# ipro7 register map
Vendor: intelpro; Series: BTBLE
CPU: ipro7, little endian
Registers are 32-bit, read-write, reset 0x0 unless marked. A register's access mark holds for its fields unless they carry their own. Offsets are from the block's base; [hi:lo] are bit positions; {n}, {i} and the like mark numbered series; <NAME> marks a mode.

## DMA
Base 0x30082000
0x00 DMA_IntStatus (reset mask 0xFFFFFF00)
  [7:0] IntStatus ro — Status of the DMA interrupts after masking
0x04 DMA_IntTCStatus (reset mask 0xFFFFFF00)
  [7:0] IntTCStatus ro — Interrupt terminal count request status
0x08 DMA_IntTCClear
  [7:0] IntTCClear wo — Terminal count request clear
0x0C DMA_IntErrorStatus (reset mask 0xFFFFFF00)
  [7:0] IntErrorStatus ro — Interrupt error status
0x10 DMA_IntErrClr
  [7:0] IntErrClr wo — Interrupt error clear
0x14 DMA_RawIntTCStatus (reset mask 0xFFFFFF00)
  [7:0] RawIntTCStatus ro — Status of the terminal count interrupt prior to masking
0x18 DMA_RawIntErrorStatus (reset mask 0xFFFFFF00)
  [7:0] RawIntErrorStatus ro — Status of the error interrupt prior to masking
0x1C DMA_EnbldChns (reset mask 0xFFFFFF00)
  [7:0] EnabledChannels ro — Channel enable status
0x20 DMA_SoftBReq
  [31:0] SoftBReq — Software burst request
0x24 DMA_SoftSReq
  [31:0] SoftSReq — Software single request
0x28 DMA_SoftLBReq
  [31:0] SoftLBReq — Software last burst request
0x2C DMA_SoftLSReq
  [31:0] SoftLSReq — Software last single request
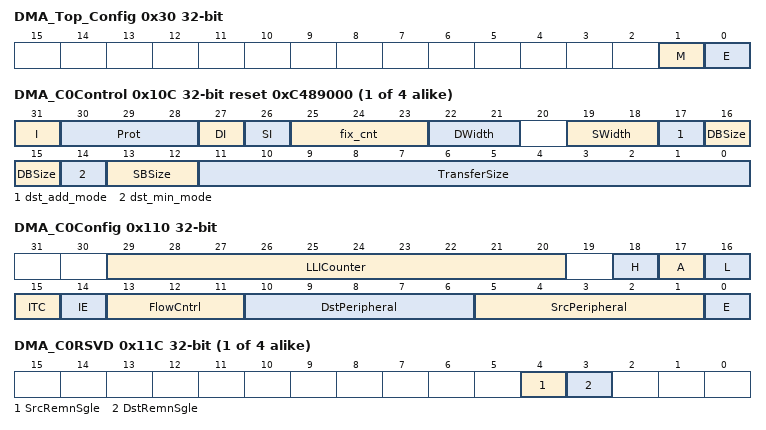
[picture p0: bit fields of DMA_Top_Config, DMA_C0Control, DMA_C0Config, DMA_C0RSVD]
0x30 DMA_Top_Config
  [1] M — AHB Master endianness configuration: 0 = little-endian, 1 = big-endian
  [0] E — SMDMA Enable.
0x34 DMA_Sync
  [31:0] DMA_Sync — DMA synchronization logic for DMA request signals: 0 = enable, 1 = disable
0x100 DMA_C0SrcAddr
  [31:0] SrcAddr — DMA source address
0x104 DMA_C0DstAddr
  [31:0] DstAddr — DMA Destination address
0x108 DMA_C0LLI
  [31:0] LLI — First linked list item. Bits [1:0] must be 0.
{0x10C+0x100*i} DMA_C{i}Control reset 0xC489000 (i=0..3)
  [31] I — Terminal count interrupt enable bit. It controls whether the current LLI is expected to trigger the terminal count interrupt.
  [30:28] Prot — No use for currently
  [27] DI — Destination increment. When set, the Destination address is incremented after each transfer.
  [26] SI — Source increment. When set, the source address is incremented after each transfer.
  [25:23] fix_cnt — Only effect when dst_min_mode = 1 Destination transfer cnt = (total src byte cnt - (fix_cnt<<DWidth))<<DWidth
  [22:21] DWidth — Destination transfer width: 2'b00 : byte 2'b01 : half-word 2'b10 : word 2'b11 : double-word
  [19:18] SWidth — Source transfer width 2'b00 : byte 2'b01 : half-word 2'b10 : word 2'b11 : double-word
  [17] dst_add_mode — Add mode : issue remain destination traffic
  [16:15] DBSize — Destination burst size 2'b00 : INCR1 2'b01 : INCR4 2'b10 : INCR8 2'b11 : INCR16 Note : SBSize*Swidth should <= CH FIFO Size
  [14] dst_min_mode — Minus mode : Not issue all destination traffic
  [13:12] SBSize — Source burst size: 2'b00 : INCR1 2'b01 : INCR4 2'b10 : INCR8 2'b11 : INCR16 Note : SBSize*Swidth should <= CH FIFO Size
  [11:0] TransferSize — Transfer size: 0~4095. Number of data transfers left to complete when the SMDMA is the flow controller.
0x110 DMA_C0Config (reset mask 0xC00DFFFF)
  [29:20] LLICounter ro — LLI counter. Increased 1 each LLI run. Cleared 0 when config Control.
  [18] H — Halt: 0 = enable DMA requests, 1 = ignore subsequent source DMA requests.
  [17] A ro — Active: 0 = no data in FIFO of the channel, 1 = FIFO of the channel has data.
  [16] L — Lock.
  [15] ITC — Terminal count interrupt mask.
  [14] IE — Interrupt error mask.
  [13:11] FlowCntrl — 000: Memory-to-memory (DMA) 001: Memory-to-peripheral (DMA) 010: Peripheral-to-memory (DMA) 011: Source peripheral-to-Destination peripheral (DMA) 100: Source peripheral-to-Destination peripheral (Destination peripheral) 101: Memory-to-peripheral (peripheral) 110: Peripheral-to-memory (peripheral) 111: Source peripheral-to-Destination peripheral (Source peripheral)
  [10:6] DstPeripheral — Destination peripheral.
  [5:1] SrcPeripheral — Source peripheral.
  [0] E — Channel enable.
{0x11C+0x100*i} DMA_C{i}RSVD (i=0..3)
  [4] SrcRemnSgle — Source remain single issue mode
  [3] DstRemnSgle — Destination remain single issue mode
{0x100+0x100*i} DMA_C{i}SrcAddr (i=1..3)
  [31:0] SrcAddr
{0x104+0x100*i} DMA_C{i}DstAddr (i=1..3)
  [31:0] DstAddr
{0x108+0x100*i} DMA_C{i}LLI (i=1..3)
  [31:0] LLI
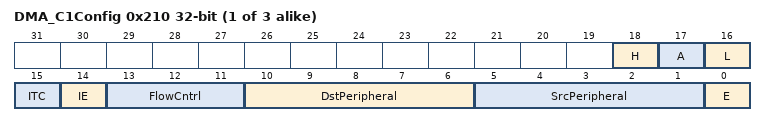
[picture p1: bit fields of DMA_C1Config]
{0x110+0x100*i} DMA_C{i}Config (reset mask 0xFFFDFFFF) (i=1..3)
  [18] H, [17] A ro, [16] L, [15] ITC, [14] IE, [13:11] FlowCntrl, [10:6] DstPeripheral, [5:1] SrcPeripheral, [0] E
